# CTRL_MMR0_CFG0 register map
Vendor: Texas Instruments
Registers are 32-bit, read-write, reset 0x0 unless marked. A register's access mark holds for its fields unless they carry their own. Offsets are as the file gives them; [hi:lo] are bit positions; {n}, {i} and the like mark numbered series.

## CTRL_MMR0_CFG0 (part 5 of 10)
0x6504 CFG0_GPU0_GP_IN_ACK_PROXY ro — Acknowledge for GPIO input event from GPU0
  [15] GPU0_GP_IN_ACK_ACK_PROXY — Input acknowledge. The GPU will set this bit to acknowledge a GPIO input request. This will generate a gpu_gpio_ack interrupt which will be cleared when the requestor clears the req bit in the GPU_GP_IN_REQ register.
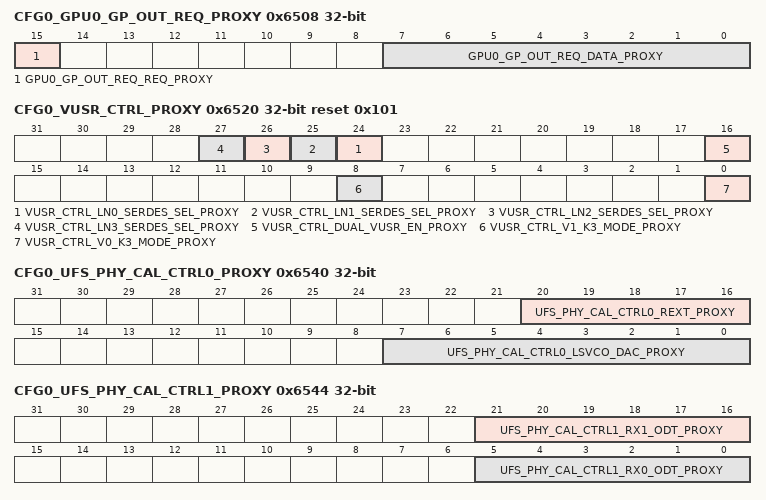
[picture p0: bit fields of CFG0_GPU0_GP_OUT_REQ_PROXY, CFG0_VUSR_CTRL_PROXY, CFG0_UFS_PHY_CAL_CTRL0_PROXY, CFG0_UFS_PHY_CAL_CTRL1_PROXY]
0x6508 CFG0_GPU0_GP_OUT_REQ_PROXY ro — Generates GPIO output event from GPU0
  [15] GPU0_GP_OUT_REQ_REQ_PROXY — Output request. This bit is set to generate a GPIO request from the GPU to read the requestor data output. This will generate a gpu_gpio_req interrupt which will be cleared when the receiver clears the ack bit in the GPU_GPIO_OUT_ACK register. This bit will be cleared by the GPU after the request has been acknowledged.
  [7:0] GPU0_GP_OUT_REQ_DATA_PROXY — GPIO requestor data output from the GPU
0x650C CFG0_GPU0_GP_OUT_ACK_PROXY — Acknowledge for GPIO output event to GPU0
  [15] GPU0_GP_OUT_ACK_ACK_PROXY — Output acknowledge. The receiver of the gpu_gpio_req interrupt will set this bit to acknowledge the GPIO output request. This bit is cleared when the GPU deasserts its gpio_output_req signal.
0x6520 CFG0_VUSR_CTRL_PROXY reset 0x101 — Controls operation of the dual VUSR (Hyperlink) module
  [n+24] VUSR_CTRL_LN{n}_SERDES_SEL_PROXY (n=0..3) — Serdes Selection - Lane {n}The Hyperlink lane{n} interface can be mapped to 2 different SERDES lanes. This bit selects which SERDES drives the VUSR lane{n} PIPE interface input clock, data and control signals. Programming should align with the SERDES0_LN{n}_CTRL and SERDES4_LN{n}_CTRL lane_func_sel programming. 0 - SERDES0 Ln{n} drives VUSR lane{n} inputs 1 - SERDES4 Ln{n} drives VUSR lane{n} inputs
  [16] VUSR_CTRL_DUAL_VUSR_EN_PROXY — Selects single or dual VUSR interface operation 0 - Single VUSR interface (VUSR0) enabled 1 - Dual VUSR interface (VUSR0 & VUSR1) enabled
  [8] VUSR_CTRL_V1_K3_MODE_PROXY — VUSR1 interface operational mode 0 - Legacy (KS2) addressing/interface mode 1 - Enhanced (KS3) addressing/interface mode
  [0] VUSR_CTRL_V0_K3_MODE_PROXY — VUSR0 interface operational mode 0 - Legacy (KS2) addressing/interface mode 1 - Enhanced (KS3) addressing/interface mode
0x6540 CFG0_UFS_PHY_CAL_CTRL0_PROXY — Controls UFS LSVCO calibration
  [20:16] UFS_PHY_CAL_CTRL0_REXT_PROXY — REXT calibration trim value
  [7:0] UFS_PHY_CAL_CTRL0_LSVCO_DAC_PROXY — LS VCO calibration trim value
0x6544 CFG0_UFS_PHY_CAL_CTRL1_PROXY — Controls UFS RX calibration
  [21:16] UFS_PHY_CAL_CTRL1_RX1_ODT_PROXY — RX1 DP/DN 100-ohm differential impedance trim value
  [5:0] UFS_PHY_CAL_CTRL1_RX0_ODT_PROXY — RX0 DP/DN 100-ohm differential impedance trim value
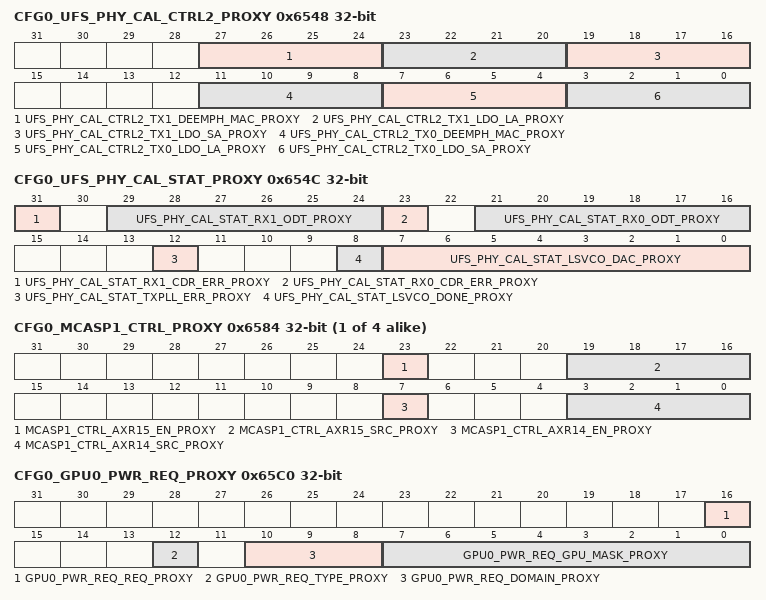
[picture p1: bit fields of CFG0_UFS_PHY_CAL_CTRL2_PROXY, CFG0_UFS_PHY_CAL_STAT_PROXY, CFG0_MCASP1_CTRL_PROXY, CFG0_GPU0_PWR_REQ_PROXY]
0x6548 CFG0_UFS_PHY_CAL_CTRL2_PROXY — Controls UFS TX calibration
  [27:24] UFS_PHY_CAL_CTRL2_TX1_DEEMPH_MAC_PROXY — TX1 DP/DN de-emphasis trim value
  [23:20] UFS_PHY_CAL_CTRL2_TX1_LDO_LA_PROXY — TX1 DP/DN large amplitude trim value
  [19:16] UFS_PHY_CAL_CTRL2_TX1_LDO_SA_PROXY — TX1 DP/DN small amplitude trim value
  [11:8] UFS_PHY_CAL_CTRL2_TX0_DEEMPH_MAC_PROXY — TX0 DP/DN de-emphasis trim value
  [7:4] UFS_PHY_CAL_CTRL2_TX0_LDO_LA_PROXY — TX0 DP/DN large amplitude trim value
  [3:0] UFS_PHY_CAL_CTRL2_TX0_LDO_SA_PROXY — TX0 DP/DN small amplitude trim value
0x654C CFG0_UFS_PHY_CAL_STAT_PROXY ro — Shows UFS calibration procedure results
  [31] UFS_PHY_CAL_STAT_RX1_CDR_ERR_PROXY — RX1 CDR calibration timeout error
  [29:24] UFS_PHY_CAL_STAT_RX1_ODT_PROXY — RX1 DP/DN ODT calibration result
  [23] UFS_PHY_CAL_STAT_RX0_CDR_ERR_PROXY — RX0 CDR calibration timeout error
  [21:16] UFS_PHY_CAL_STAT_RX0_ODT_PROXY — RX0 DP/DN ODT calibration result
  [12] UFS_PHY_CAL_STAT_TXPLL_ERR_PROXY — TX calibration timeout error
  [8] UFS_PHY_CAL_STAT_LSVCO_DONE_PROXY — LS VCO calibration trim done
  [7:0] UFS_PHY_CAL_STAT_LSVCO_DAC_PROXY — LS VCO calibration trim result
{0x6580+4i} CFG0_MCASP{i}_CTRL_PROXY (i=1..4) — Controls McASP{i} operation
  [23] MCASP{i}_CTRL_AXR15_EN_PROXY — Enable AXR15 receive data. 0 - AXR15 input driven 1'b0 1 - AXR15 input driven by AFSR/X input selected by axr15_src value
  [19:16] MCASP{i}_CTRL_AXR15_SRC_PROXY — Selects one of the AFSX or AFSR inputs as the AXR15 data input Field values (Others are reserved): 4'b0000 - McASP0_AFSR 4'b0001 - McASP0_AFSX 4'b0010 - McASP1_AFSR 4'b0011 - McASP1_AFSX 4'b0100 - McASP2_AFSR 4'b0101 - McASP2_AFSX 4'b0110 - McASP3_AFSR 4'b0111 - McASP3_AFSX 4'b1000 - McASP4_AFSR 4'b1001 - McASP4_AFSX 4'b1010 - 0 4'b1011 - 0 4'b1100 - 0 4'b1101 - 0 4'b1110 - 0 4'b1111 - 0
  [7] MCASP{i}_CTRL_AXR14_EN_PROXY — Enable AXR14 receive data. 0 - AXR14 input driven 1'b0 1 - AXR14 input driven by AFSR/X input selected by axr14_src value
  [3:0] MCASP{i}_CTRL_AXR14_SRC_PROXY — Selects one of the AFSX or AFSR inputs as the AXR14 data input Field values (Others are reserved): 4'b0000 - McASP0_AFSR 4'b0001 - McASP0_AFSX 4'b0010 - McASP1_AFSR 4'b0011 - McASP1_AFSX 4'b0100 - McASP2_AFSR 4'b0101 - McASP2_AFSX 4'b0110 - McASP3_AFSR 4'b0111 - McASP3_AFSX 4'b1000 - McASP4_AFSR 4'b1001 - McASP4_AFSX 4'b1010 - 0 4'b1011 - 0 4'b1100 - 0 4'b1101 - 0 4'b1110 - 0 4'b1111 - 0
0x65C0 CFG0_GPU0_PWR_REQ_PROXY ro — Indicates GPU0 power control interface requests
  [16] GPU0_PWR_REQ_REQ_PROXY — Power control request. This bit is set by the GPU to request a Power Management event to the PM processor. This will generate a gpu0_pwr_req interrupt. The interrupt is cleared only when the GPU clears its pwrctrl_gpu_req output.
  [12] GPU0_PWR_REQ_TYPE_PROXY — GPU request type. 0 - Power Down request 1 - Power Up request
  [10:8] GPU0_PWR_REQ_DOMAIN_PROXY — GPU request mask. Indicates GPU domain to which the power event applies. For mapping refer to GPU RGX_CR_POWER_EVENT register.
  [7:0] GPU0_PWR_REQ_GPU_MASK_PROXY — GPU request mask. One bit per GPU indicating to which GPUs the power event applies. Mask bits are indexed by GPU_ID
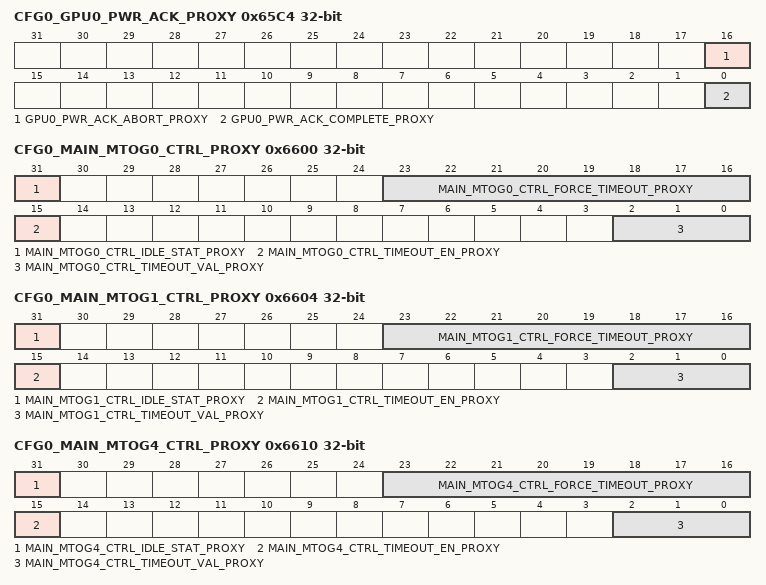
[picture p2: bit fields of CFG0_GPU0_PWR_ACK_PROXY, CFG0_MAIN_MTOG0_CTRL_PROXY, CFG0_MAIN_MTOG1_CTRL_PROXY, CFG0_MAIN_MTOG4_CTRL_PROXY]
0x65C4 CFG0_GPU0_PWR_ACK_PROXY — Controls GPU0 power control interface request acknowledgement
  [16] GPU0_PWR_ACK_ABORT_PROXY — Power control abort. This bit is set by the PM processor to that the GPU power control request could not be completed. The bit is cleared to 0 when gpu0_pwr_req goes low.
  [0] GPU0_PWR_ACK_COMPLETE_PROXY — Power control complete. This bit is set by the PM processor to indicate sucessful completion of the GPU power control request. The bit is cleared to 0 when gpu0_pwr_req goes low.
0x6600 CFG0_MAIN_MTOG0_CTRL_PROXY access per field — Controls timeout operation of read transactions from the GIC master port
  [31] MAIN_MTOG0_CTRL_IDLE_STAT_PROXY ro — Idle statusWhen high, indicates MTOG0 is idle.
  [23:16] MAIN_MTOG0_CTRL_FORCE_TIMEOUT_PROXY rw — Force TimeoutForces a flush of the interface transactions. This bitfield is only relevant if timeout_en=1. After forcing a timeout by writing the encoded value, the force_timeout and timeout_en bitfields must be cleared to clear the timeout before re-enabling the gasket. 8'h95 - Force a gasket timeoutAll others - Normal operation
  [15] MAIN_MTOG0_CTRL_TIMEOUT_EN_PROXY rw — Timeout Enable 1'b0 - Disable the gasket. Clear the interrupt and reset the counter 1'b1 - Enable the timeout gasket functions
  [2:0] MAIN_MTOG0_CTRL_TIMEOUT_VAL_PROXY rw — Gasket Timeout ValueSelects the number of clock cycles before the interface is considered to have timed out Field values (Others are reserved): 3'b000 - 1024 clock cycles 3'b001 - 4096 clock cycles 3'b010 - 16,384 clock cycles 3'b011 - 65,536 clock cycles 3'b100 - 262,144 clock cycles 3'b101 - 1,048,576 clock cycles 3'b110 - 2,097,152 clock cycles 3'b111 - 4,194,303 clock cycles
0x6604 CFG0_MAIN_MTOG1_CTRL_PROXY access per field — Controls timeout operation of write transactions from the GIC master port
  [31] MAIN_MTOG1_CTRL_IDLE_STAT_PROXY ro — Idle statusWhen high, indicates MTOG1 is idle.
  [23:16] MAIN_MTOG1_CTRL_FORCE_TIMEOUT_PROXY rw — Force TimeoutForces a flush of the interface transactions. This bitfield is only relevant if timeout_en=1. After forcing a timeout by writing the encoded value, the force_timeout and timeout_en bitfields must be cleared to clear the timeout before re-enabling the gasket. 8'h95 - Force a gasket timeoutAll others - Normal operation
  [15] MAIN_MTOG1_CTRL_TIMEOUT_EN_PROXY rw — Timeout Enable 1'b0 - Disable the gasket. Clear the interrupt and reset the counter 1'b1 - Enable the timeout gasket functions
  [2:0] MAIN_MTOG1_CTRL_TIMEOUT_VAL_PROXY rw — Gasket Timeout ValueSelects the number of clock cycles before the interface is considered to have timed out Field values (Others are reserved): 3'b000 - 1024 clock cycles 3'b001 - 4096 clock cycles 3'b010 - 16,384 clock cycles 3'b011 - 65,536 clock cycles 3'b100 - 262,144 clock cycles 3'b101 - 1,048,576 clock cycles 3'b110 - 2,097,152 clock cycles 3'b111 - 4,194,303 clock cycles
0x6610 CFG0_MAIN_MTOG4_CTRL_PROXY access per field — Controls timeout operation of read transactions from the eMMC1 master port
  [31] MAIN_MTOG4_CTRL_IDLE_STAT_PROXY ro — Idle statusWhen high, indicates MTOG4 is idle.
  [23:16] MAIN_MTOG4_CTRL_FORCE_TIMEOUT_PROXY rw — Force TimeoutForces a flush of the interface transactions. This bitfield is only relevant if timeout_en=1. After forcing a timeout by writing the encoded value, the force_timeout and timeout_en bitfields must be cleared to clear the timeout before re-enabling the gasket. 8'h95 - Force a gasket timeoutAll others - Normal operation
  [15] MAIN_MTOG4_CTRL_TIMEOUT_EN_PROXY rw — Timeout Enable 1'b0 - Disable the gasket. Clear the interrupt and reset the counter 1'b1 - Enable the timeout gasket functions
  [2:0] MAIN_MTOG4_CTRL_TIMEOUT_VAL_PROXY rw — Gasket Timeout ValueSelects the number of clock cycles before the interface is considered to have timed out Field values (Others are reserved): 3'b000 - 1024 clock cycles 3'b001 - 4096 clock cycles 3'b010 - 16,384 clock cycles 3'b011 - 65,536 clock cycles 3'b100 - 262,144 clock cycles 3'b101 - 1,048,576 clock cycles 3'b110 - 2,097,152 clock cycles 3'b111 - 4,194,303 clock cycles
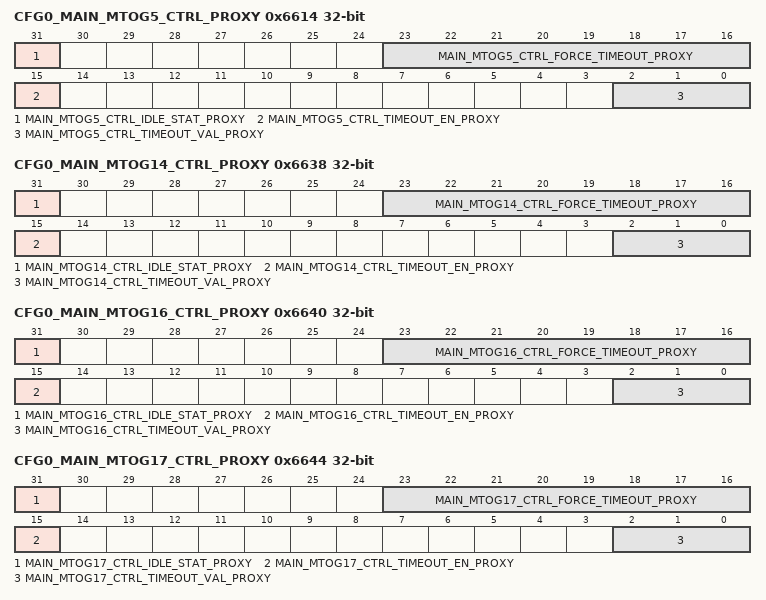
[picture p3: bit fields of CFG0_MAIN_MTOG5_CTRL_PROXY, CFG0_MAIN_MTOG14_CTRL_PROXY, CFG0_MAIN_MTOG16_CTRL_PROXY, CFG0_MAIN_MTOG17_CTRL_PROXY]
0x6614 CFG0_MAIN_MTOG5_CTRL_PROXY access per field — Controls timeout operation of write transactions from the eMMC1 master port
  [31] MAIN_MTOG5_CTRL_IDLE_STAT_PROXY ro — Idle statusWhen high, indicates MTOG5 is idle.
  [23:16] MAIN_MTOG5_CTRL_FORCE_TIMEOUT_PROXY rw — Force TimeoutForces a flush of the interface transactions. This bitfield is only relevant if timeout_en=1. After forcing a timeout by writing the encoded value, the force_timeout and timeout_en bitfields must be cleared to clear the timeout before re-enabling the gasket. 8'h95 - Force a gasket timeoutAll others - Normal operation
  [15] MAIN_MTOG5_CTRL_TIMEOUT_EN_PROXY rw — Timeout Enable 1'b0 - Disable the gasket. Clear the interrupt and reset the counter 1'b1 - Enable the timeout gasket functions
  [2:0] MAIN_MTOG5_CTRL_TIMEOUT_VAL_PROXY rw — Gasket Timeout ValueSelects the number of clock cycles before the interface is considered to have timed out Field values (Others are reserved): 3'b000 - 1024 clock cycles 3'b001 - 4096 clock cycles 3'b010 - 16,384 clock cycles 3'b011 - 65,536 clock cycles 3'b100 - 262,144 clock cycles 3'b101 - 1,048,576 clock cycles 3'b110 - 2,097,152 clock cycles 3'b111 - 4,194,303 clock cycles
0x6638 CFG0_MAIN_MTOG14_CTRL_PROXY access per field — Controls timeout operation of transactions from the NavSS PVU to VIRTSS
  [31] MAIN_MTOG14_CTRL_IDLE_STAT_PROXY ro — Idle statusWhen high, indicates MTOG14 is idle.
  [23:16] MAIN_MTOG14_CTRL_FORCE_TIMEOUT_PROXY rw — Force TimeoutForces a flush of the interface transactions. This bitfield is only relevant if timeout_en=1. After forcing a timeout by writing the encoded value, the force_timeout and timeout_en bitfields must be cleared to clear the timeout before re-enabling the gasket. 8'h95 - Force a gasket timeoutAll others - Normal operation
  [15] MAIN_MTOG14_CTRL_TIMEOUT_EN_PROXY rw — Timeout Enable 1'b0 - Disable the gasket. Clear the interrupt and reset the counter 1'b1 - Enable the timeout gasket functions
  [2:0] MAIN_MTOG14_CTRL_TIMEOUT_VAL_PROXY rw — Gasket Timeout ValueSelects the number of clock cycles before the interface is considered to have timed out Field values (Others are reserved): 3'b000 - 1024 clock cycles 3'b001 - 4096 clock cycles 3'b010 - 16,384 clock cycles 3'b011 - 65,536 clock cycles 3'b100 - 262,144 clock cycles 3'b101 - 1,048,576 clock cycles 3'b110 - 2,097,152 clock cycles 3'b111 - 4,194,303 clock cycles
0x6640 CFG0_MAIN_MTOG16_CTRL_PROXY access per field — Controls timeout operation of read transactions from the MAIN R5 Clstr0 Core0 VBUSM Memory master port
  [31] MAIN_MTOG16_CTRL_IDLE_STAT_PROXY ro — Idle statusWhen high, indicates MTOG16 is idle.
  [23:16] MAIN_MTOG16_CTRL_FORCE_TIMEOUT_PROXY rw — Force TimeoutForces a flush of the interface transactions. This bitfield is only relevant if timeout_en=1. After forcing a timeout by writing the encoded value, the force_timeout and timeout_en bitfields must be cleared to clear the timeout before re-enabling the gasket. 8'h95 - Force a gasket timeoutAll others - Normal operation
  [15] MAIN_MTOG16_CTRL_TIMEOUT_EN_PROXY rw — Timeout Enable 1'b0 - Disable the gasket. Clear the interrupt and reset the counter 1'b1 - Enable the timeout gasket functions
  [2:0] MAIN_MTOG16_CTRL_TIMEOUT_VAL_PROXY rw — Gasket Timeout ValueSelects the number of clock cycles before the interface is considered to have timed out Field values (Others are reserved): 3'b000 - 1024 clock cycles 3'b001 - 4096 clock cycles 3'b010 - 16,384 clock cycles 3'b011 - 65,536 clock cycles 3'b100 - 262,144 clock cycles 3'b101 - 1,048,576 clock cycles 3'b110 - 2,097,152 clock cycles 3'b111 - 4,194,303 clock cycles
0x6644 CFG0_MAIN_MTOG17_CTRL_PROXY access per field — Controls timeout operation of write transactions from the MAIN R5 Clstr0 Core0 VBUSM Memory master port
  [31] MAIN_MTOG17_CTRL_IDLE_STAT_PROXY ro — Idle statusWhen high, indicates MTOG17 is idle.
  [23:16] MAIN_MTOG17_CTRL_FORCE_TIMEOUT_PROXY rw — Force TimeoutForces a flush of the interface transactions. This bitfield is only relevant if timeout_en=1. After forcing a timeout by writing the encoded value, the force_timeout and timeout_en bitfields must be cleared to clear the timeout before re-enabling the gasket. 8'h95 - Force a gasket timeoutAll others - Normal operation
  [15] MAIN_MTOG17_CTRL_TIMEOUT_EN_PROXY rw — Timeout Enable 1'b0 - Disable the gasket. Clear the interrupt and reset the counter 1'b1 - Enable the timeout gasket functions
  [2:0] MAIN_MTOG17_CTRL_TIMEOUT_VAL_PROXY rw — Gasket Timeout ValueSelects the number of clock cycles before the interface is considered to have timed out Field values (Others are reserved): 3'b000 - 1024 clock cycles 3'b001 - 4096 clock cycles 3'b010 - 16,384 clock cycles 3'b011 - 65,536 clock cycles 3'b100 - 262,144 clock cycles 3'b101 - 1,048,576 clock cycles 3'b110 - 2,097,152 clock cycles 3'b111 - 4,194,303 clock cycles
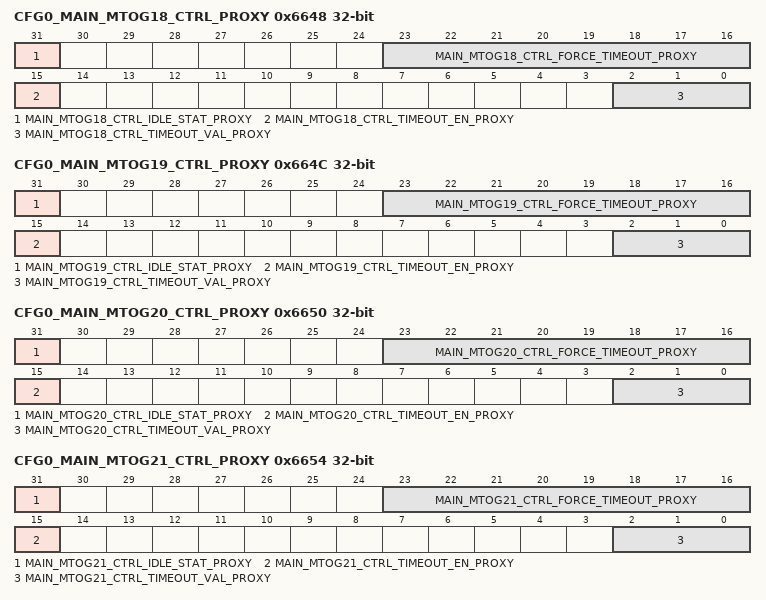
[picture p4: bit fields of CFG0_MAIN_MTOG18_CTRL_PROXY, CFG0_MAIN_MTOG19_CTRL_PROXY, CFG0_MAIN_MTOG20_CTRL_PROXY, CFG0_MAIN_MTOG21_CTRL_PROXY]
0x6648 CFG0_MAIN_MTOG18_CTRL_PROXY access per field — Controls timeout operation of read transactions from the MAIN R5 Clstr0 Core1 VBUSM Memory master port
  [31] MAIN_MTOG18_CTRL_IDLE_STAT_PROXY ro — Idle statusWhen high, indicates MTOG18 is idle.
  [23:16] MAIN_MTOG18_CTRL_FORCE_TIMEOUT_PROXY rw — Force TimeoutForces a flush of the interface transactions. This bitfield is only relevant if timeout_en=1. After forcing a timeout by writing the encoded value, the force_timeout and timeout_en bitfields must be cleared to clear the timeout before re-enabling the gasket. 8'h95 - Force a gasket timeoutAll others - Normal operation
  [15] MAIN_MTOG18_CTRL_TIMEOUT_EN_PROXY rw — Timeout Enable 1'b0 - Disable the gasket. Clear the interrupt and reset the counter 1'b1 - Enable the timeout gasket functions
  [2:0] MAIN_MTOG18_CTRL_TIMEOUT_VAL_PROXY rw — Gasket Timeout ValueSelects the number of clock cycles before the interface is considered to have timed out Field values (Others are reserved): 3'b000 - 1024 clock cycles 3'b001 - 4096 clock cycles 3'b010 - 16,384 clock cycles 3'b011 - 65,536 clock cycles 3'b100 - 262,144 clock cycles 3'b101 - 1,048,576 clock cycles 3'b110 - 2,097,152 clock cycles 3'b111 - 4,194,303 clock cycles
0x664C CFG0_MAIN_MTOG19_CTRL_PROXY access per field — Controls timeout operation of write transactions from the MAIN R5 Clstr0 Core1 VBUSM Memory master port
  [31] MAIN_MTOG19_CTRL_IDLE_STAT_PROXY ro — Idle statusWhen high, indicates MTOG19 is idle.
  [23:16] MAIN_MTOG19_CTRL_FORCE_TIMEOUT_PROXY rw — Force TimeoutForces a flush of the interface transactions. This bitfield is only relevant if timeout_en=1. After forcing a timeout by writing the encoded value, the force_timeout and timeout_en bitfields must be cleared to clear the timeout before re-enabling the gasket. 8'h95 - Force a gasket timeoutAll others - Normal operation
  [15] MAIN_MTOG19_CTRL_TIMEOUT_EN_PROXY rw — Timeout Enable 1'b0 - Disable the gasket. Clear the interrupt and reset the counter 1'b1 - Enable the timeout gasket functions
  [2:0] MAIN_MTOG19_CTRL_TIMEOUT_VAL_PROXY rw — Gasket Timeout ValueSelects the number of clock cycles before the interface is considered to have timed out Field values (Others are reserved): 3'b000 - 1024 clock cycles 3'b001 - 4096 clock cycles 3'b010 - 16,384 clock cycles 3'b011 - 65,536 clock cycles 3'b100 - 262,144 clock cycles 3'b101 - 1,048,576 clock cycles 3'b110 - 2,097,152 clock cycles 3'b111 - 4,194,303 clock cycles
0x6650 CFG0_MAIN_MTOG20_CTRL_PROXY access per field — Controls timeout operation of read transactions from the MAIN R5 Clstr1 Core0 VBUSM Memory master port
  [31] MAIN_MTOG20_CTRL_IDLE_STAT_PROXY ro — Idle statusWhen high, indicates MTOG20 is idle.
  [23:16] MAIN_MTOG20_CTRL_FORCE_TIMEOUT_PROXY rw — Force TimeoutForces a flush of the interface transactions. This bitfield is only relevant if timeout_en=1. After forcing a timeout by writing the encoded value, the force_timeout and timeout_en bitfields must be cleared to clear the timeout before re-enabling the gasket. 8'h95 - Force a gasket timeoutAll others - Normal operation
  [15] MAIN_MTOG20_CTRL_TIMEOUT_EN_PROXY rw — Timeout Enable 1'b0 - Disable the gasket. Clear the interrupt and reset the counter 1'b1 - Enable the timeout gasket functions
  [2:0] MAIN_MTOG20_CTRL_TIMEOUT_VAL_PROXY rw — Gasket Timeout ValueSelects the number of clock cycles before the interface is considered to have timed out Field values (Others are reserved): 3'b000 - 1024 clock cycles 3'b001 - 4096 clock cycles 3'b010 - 16,384 clock cycles 3'b011 - 65,536 clock cycles 3'b100 - 262,144 clock cycles 3'b101 - 1,048,576 clock cycles 3'b110 - 2,097,152 clock cycles 3'b111 - 4,194,303 clock cycles
0x6654 CFG0_MAIN_MTOG21_CTRL_PROXY access per field — Controls timeout operation of write transactions from the MAIN R5 Clstr1 Core0 VBUSM Memory master port
  [31] MAIN_MTOG21_CTRL_IDLE_STAT_PROXY ro — Idle statusWhen high, indicates MTOG21 is idle.
  [23:16] MAIN_MTOG21_CTRL_FORCE_TIMEOUT_PROXY rw — Force TimeoutForces a flush of the interface transactions. This bitfield is only relevant if timeout_en=1. After forcing a timeout by writing the encoded value, the force_timeout and timeout_en bitfields must be cleared to clear the timeout before re-enabling the gasket. 8'h95 - Force a gasket timeoutAll others - Normal operation
  [15] MAIN_MTOG21_CTRL_TIMEOUT_EN_PROXY rw — Timeout Enable 1'b0 - Disable the gasket. Clear the interrupt and reset the counter 1'b1 - Enable the timeout gasket functions
  [2:0] MAIN_MTOG21_CTRL_TIMEOUT_VAL_PROXY rw — Gasket Timeout ValueSelects the number of clock cycles before the interface is considered to have timed out Field values (Others are reserved): 3'b000 - 1024 clock cycles 3'b001 - 4096 clock cycles 3'b010 - 16,384 clock cycles 3'b011 - 65,536 clock cycles 3'b100 - 262,144 clock cycles 3'b101 - 1,048,576 clock cycles 3'b110 - 2,097,152 clock cycles 3'b111 - 4,194,303 clock cycles
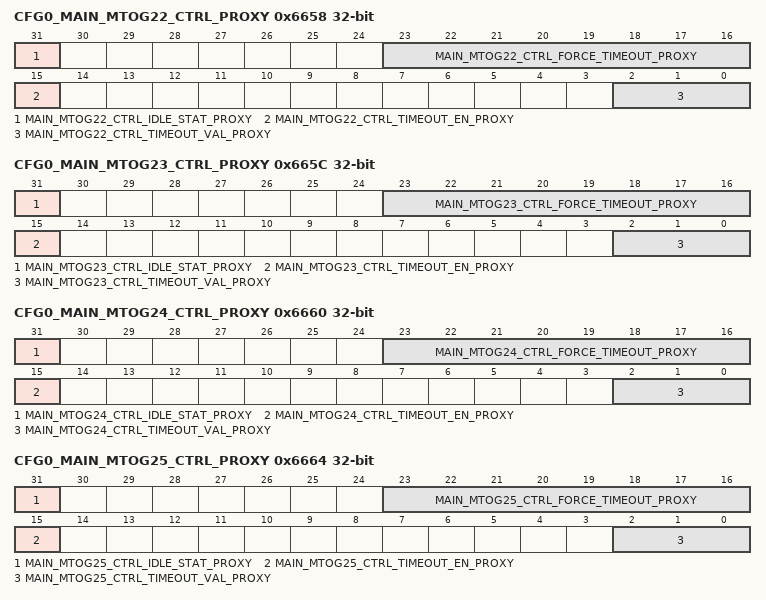
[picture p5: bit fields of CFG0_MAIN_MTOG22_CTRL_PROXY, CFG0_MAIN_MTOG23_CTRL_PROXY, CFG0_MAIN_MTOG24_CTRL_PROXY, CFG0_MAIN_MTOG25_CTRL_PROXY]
0x6658 CFG0_MAIN_MTOG22_CTRL_PROXY access per field — Controls timeout operation of read transactions from the MAIN R5 Clstr1 Core1 VBUSM Memory master port
  [31] MAIN_MTOG22_CTRL_IDLE_STAT_PROXY ro — Idle statusWhen high, indicates MTOG22 is idle.
  [23:16] MAIN_MTOG22_CTRL_FORCE_TIMEOUT_PROXY rw — Force TimeoutForces a flush of the interface transactions. This bitfield is only relevant if timeout_en=1. After forcing a timeout by writing the encoded value, the force_timeout and timeout_en bitfields must be cleared to clear the timeout before re-enabling the gasket. 8'h95 - Force a gasket timeoutAll others - Normal operation
  [15] MAIN_MTOG22_CTRL_TIMEOUT_EN_PROXY rw — Timeout Enable 1'b0 - Disable the gasket. Clear the interrupt and reset the counter 1'b1 - Enable the timeout gasket functions
  [2:0] MAIN_MTOG22_CTRL_TIMEOUT_VAL_PROXY rw — Gasket Timeout ValueSelects the number of clock cycles before the interface is considered to have timed out Field values (Others are reserved): 3'b000 - 1024 clock cycles 3'b001 - 4096 clock cycles 3'b010 - 16,384 clock cycles 3'b011 - 65,536 clock cycles 3'b100 - 262,144 clock cycles 3'b101 - 1,048,576 clock cycles 3'b110 - 2,097,152 clock cycles 3'b111 - 4,194,303 clock cycles
0x665C CFG0_MAIN_MTOG23_CTRL_PROXY access per field — Controls timeout operation of write transactions from the MAIN R5 Clstr1 Core 1 VBUSM Memory master port
  [31] MAIN_MTOG23_CTRL_IDLE_STAT_PROXY ro — Idle statusWhen high, indicates MTOG23 is idle.
  [23:16] MAIN_MTOG23_CTRL_FORCE_TIMEOUT_PROXY rw — Force TimeoutForces a flush of the interface transactions. This bitfield is only relevant if timeout_en=1. After forcing a timeout by writing the encoded value, the force_timeout and timeout_en bitfields must be cleared to clear the timeout before re-enabling the gasket. 8'h95 - Force a gasket timeoutAll others - Normal operation
  [15] MAIN_MTOG23_CTRL_TIMEOUT_EN_PROXY rw — Timeout Enable 1'b0 - Disable the gasket. Clear the interrupt and reset the counter 1'b1 - Enable the timeout gasket functions
  [2:0] MAIN_MTOG23_CTRL_TIMEOUT_VAL_PROXY rw — Gasket Timeout ValueSelects the number of clock cycles before the interface is considered to have timed out Field values (Others are reserved): 3'b000 - 1024 clock cycles 3'b001 - 4096 clock cycles 3'b010 - 16,384 clock cycles 3'b011 - 65,536 clock cycles 3'b100 - 262,144 clock cycles 3'b101 - 1,048,576 clock cycles 3'b110 - 2,097,152 clock cycles 3'b111 - 4,194,303 clock cycles
0x6660 CFG0_MAIN_MTOG24_CTRL_PROXY access per field — Controls timeout operation of real time transactions from High Speed IO masters
  [31] MAIN_MTOG24_CTRL_IDLE_STAT_PROXY ro — Idle statusWhen high, indicates MTOG24 is idle.
  [23:16] MAIN_MTOG24_CTRL_FORCE_TIMEOUT_PROXY rw — Force TimeoutForces a flush of the interface transactions. This bitfield is only relevant if timeout_en=1. After forcing a timeout by writing the encoded value, the force_timeout and timeout_en bitfields must be cleared to clear the timeout before re-enabling the gasket. 8'h95 - Force a gasket timeoutAll others - Normal operation
  [15] MAIN_MTOG24_CTRL_TIMEOUT_EN_PROXY rw — Timeout Enable 1'b0 - Disable the gasket. Clear the interrupt and reset the counter 1'b1 - Enable the timeout gasket functions
  [2:0] MAIN_MTOG24_CTRL_TIMEOUT_VAL_PROXY rw — Gasket Timeout ValueSelects the number of clock cycles before the interface is considered to have timed out Field values (Others are reserved): 3'b000 - 1024 clock cycles 3'b001 - 4096 clock cycles 3'b010 - 16,384 clock cycles 3'b011 - 65,536 clock cycles 3'b100 - 262,144 clock cycles 3'b101 - 1,048,576 clock cycles 3'b110 - 2,097,152 clock cycles 3'b111 - 4,194,303 clock cycles
0x6664 CFG0_MAIN_MTOG25_CTRL_PROXY access per field — Controls timeout operation of non-real time transactions from High Speed IO masters
  [31] MAIN_MTOG25_CTRL_IDLE_STAT_PROXY ro — Idle statusWhen high, indicates MTOG25 is idle.
  [23:16] MAIN_MTOG25_CTRL_FORCE_TIMEOUT_PROXY rw — Force TimeoutForces a flush of the interface transactions. This bitfield is only relevant if timeout_en=1. After forcing a timeout by writing the encoded value, the force_timeout and timeout_en bitfields must be cleared to clear the timeout before re-enabling the gasket. 8'h95 - Force a gasket timeoutAll others - Normal operation
  [15] MAIN_MTOG25_CTRL_TIMEOUT_EN_PROXY rw — Timeout Enable 1'b0 - Disable the gasket. Clear the interrupt and reset the counter 1'b1 - Enable the timeout gasket functions
  [2:0] MAIN_MTOG25_CTRL_TIMEOUT_VAL_PROXY rw — Gasket Timeout ValueSelects the number of clock cycles before the interface is considered to have timed out Field values (Others are reserved): 3'b000 - 1024 clock cycles 3'b001 - 4096 clock cycles 3'b010 - 16,384 clock cycles 3'b011 - 65,536 clock cycles 3'b100 - 262,144 clock cycles 3'b101 - 1,048,576 clock cycles 3'b110 - 2,097,152 clock cycles 3'b111 - 4,194,303 clock cycles
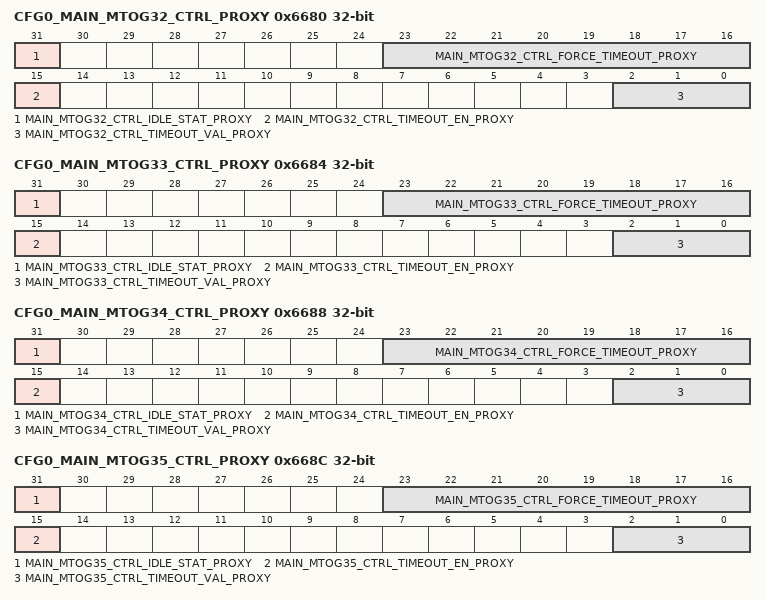
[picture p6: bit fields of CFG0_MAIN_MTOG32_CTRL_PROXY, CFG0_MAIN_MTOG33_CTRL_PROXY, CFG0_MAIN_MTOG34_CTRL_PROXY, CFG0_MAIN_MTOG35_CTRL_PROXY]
0x6680 CFG0_MAIN_MTOG32_CTRL_PROXY access per field — Controls timeout operation of Accelerator Cluster ASIL-B master accesses to MSMC (L2) SRAM
  [31] MAIN_MTOG32_CTRL_IDLE_STAT_PROXY ro — Idle statusWhen high, indicates MTOG32 is idle.
  [23:16] MAIN_MTOG32_CTRL_FORCE_TIMEOUT_PROXY rw — Force TimeoutForces a flush of the interface transactions. This bitfield is only relevant if timeout_en=1. After forcing a timeout by writing the encoded value, the force_timeout and timeout_en bitfields must be cleared to clear the timeout before re-enabling the gasket. 8'h95 - Force a gasket timeoutAll others - Normal operation
  [15] MAIN_MTOG32_CTRL_TIMEOUT_EN_PROXY rw — Timeout Enable 1'b0 - Disable the gasket. Clear the interrupt and reset the counter 1'b1 - Enable the timeout gasket functions
  [2:0] MAIN_MTOG32_CTRL_TIMEOUT_VAL_PROXY rw — Gasket Timeout ValueSelects the number of clock cycles before the interface is considered to have timed out Field values (Others are reserved): 3'b000 - 1024 clock cycles 3'b001 - 4096 clock cycles 3'b010 - 16,384 clock cycles 3'b011 - 65,536 clock cycles 3'b100 - 262,144 clock cycles 3'b101 - 1,048,576 clock cycles 3'b110 - 2,097,152 clock cycles 3'b111 - 4,194,303 clock cycles
0x6684 CFG0_MAIN_MTOG33_CTRL_PROXY access per field — Controls timeout operation of Accelerator Cluster QueueManager master accesses to MSMC (L2) SRAM
  [31] MAIN_MTOG33_CTRL_IDLE_STAT_PROXY ro — Idle statusWhen high, indicates MTOG33 is idle.
  [23:16] MAIN_MTOG33_CTRL_FORCE_TIMEOUT_PROXY rw — Force TimeoutForces a flush of the interface transactions. This bitfield is only relevant if timeout_en=1. After forcing a timeout by writing the encoded value, the force_timeout and timeout_en bitfields must be cleared to clear the timeout before re-enabling the gasket. 8'h95 - Force a gasket timeoutAll others - Normal operation
  [15] MAIN_MTOG33_CTRL_TIMEOUT_EN_PROXY rw — Timeout Enable 1'b0 - Disable the gasket. Clear the interrupt and reset the counter 1'b1 - Enable the timeout gasket functions
  [2:0] MAIN_MTOG33_CTRL_TIMEOUT_VAL_PROXY rw — Gasket Timeout ValueSelects the number of clock cycles before the interface is considered to have timed out Field values (Others are reserved): 3'b000 - 1024 clock cycles 3'b001 - 4096 clock cycles 3'b010 - 16,384 clock cycles 3'b011 - 65,536 clock cycles 3'b100 - 262,144 clock cycles 3'b101 - 1,048,576 clock cycles 3'b110 - 2,097,152 clock cycles 3'b111 - 4,194,303 clock cycles
0x6688 CFG0_MAIN_MTOG34_CTRL_PROXY access per field — Controls timeout operation of Accelerator Cluster ASIL-B master accesses to DDR for OrderIDs 0-4
  [31] MAIN_MTOG34_CTRL_IDLE_STAT_PROXY ro — Idle statusWhen high, indicates MTOG34 is idle.
  [23:16] MAIN_MTOG34_CTRL_FORCE_TIMEOUT_PROXY rw — Force TimeoutForces a flush of the interface transactions. This bitfield is only relevant if timeout_en=1. After forcing a timeout by writing the encoded value, the force_timeout and timeout_en bitfields must be cleared to clear the timeout before re-enabling the gasket. 8'h95 - Force a gasket timeoutAll others - Normal operation
  [15] MAIN_MTOG34_CTRL_TIMEOUT_EN_PROXY rw — Timeout Enable 1'b0 - Disable the gasket. Clear the interrupt and reset the counter 1'b1 - Enable the timeout gasket functions
  [2:0] MAIN_MTOG34_CTRL_TIMEOUT_VAL_PROXY rw — Gasket Timeout ValueSelects the number of clock cycles before the interface is considered to have timed out Field values (Others are reserved): 3'b000 - 1024 clock cycles 3'b001 - 4096 clock cycles 3'b010 - 16,384 clock cycles 3'b011 - 65,536 clock cycles 3'b100 - 262,144 clock cycles 3'b101 - 1,048,576 clock cycles 3'b110 - 2,097,152 clock cycles 3'b111 - 4,194,303 clock cycles
0x668C CFG0_MAIN_MTOG35_CTRL_PROXY access per field — Controls timeout operation of Accelerator Cluster QueueManager master accesses to DDR fro OrderIDs 0-4
  [31] MAIN_MTOG35_CTRL_IDLE_STAT_PROXY ro — Idle statusWhen high, indicates MTOG35 is idle.
  [23:16] MAIN_MTOG35_CTRL_FORCE_TIMEOUT_PROXY rw — Force TimeoutForces a flush of the interface transactions. This bitfield is only relevant if timeout_en=1. After forcing a timeout by writing the encoded value, the force_timeout and timeout_en bitfields must be cleared to clear the timeout before re-enabling the gasket. 8'h95 - Force a gasket timeoutAll others - Normal operation
  [15] MAIN_MTOG35_CTRL_TIMEOUT_EN_PROXY rw — Timeout Enable 1'b0 - Disable the gasket. Clear the interrupt and reset the counter 1'b1 - Enable the timeout gasket functions
  [2:0] MAIN_MTOG35_CTRL_TIMEOUT_VAL_PROXY rw — Gasket Timeout ValueSelects the number of clock cycles before the interface is considered to have timed out Field values (Others are reserved): 3'b000 - 1024 clock cycles 3'b001 - 4096 clock cycles 3'b010 - 16,384 clock cycles 3'b011 - 65,536 clock cycles 3'b100 - 262,144 clock cycles 3'b101 - 1,048,576 clock cycles 3'b110 - 2,097,152 clock cycles 3'b111 - 4,194,303 clock cycles
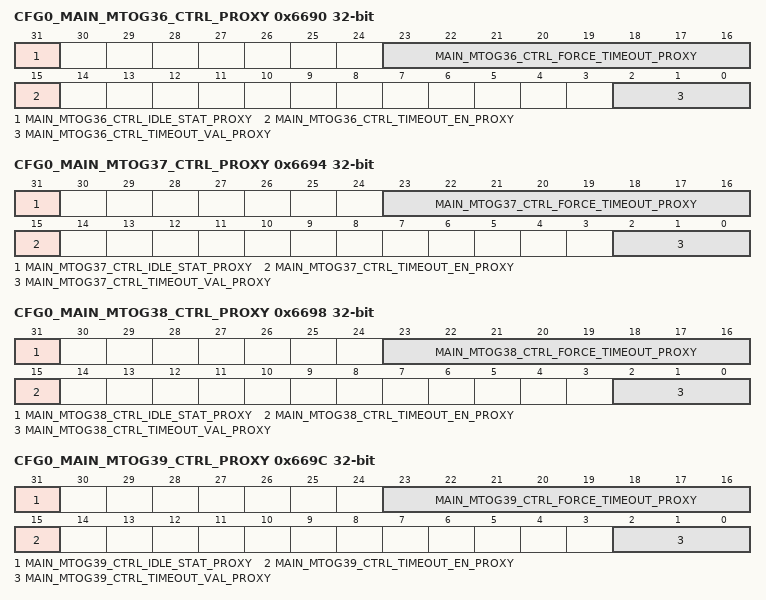
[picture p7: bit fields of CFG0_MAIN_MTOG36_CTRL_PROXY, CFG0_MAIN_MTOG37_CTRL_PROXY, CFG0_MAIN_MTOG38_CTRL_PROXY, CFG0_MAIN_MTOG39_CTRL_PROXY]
0x6690 CFG0_MAIN_MTOG36_CTRL_PROXY access per field — Controls timeout operation of Accelerator Cluster ASIL-B master accesses to DDR for OrderIDs 5-9
  [31] MAIN_MTOG36_CTRL_IDLE_STAT_PROXY ro — Idle statusWhen high, indicates MTOG36 is idle.
  [23:16] MAIN_MTOG36_CTRL_FORCE_TIMEOUT_PROXY rw — Force TimeoutForces a flush of the interface transactions. This bitfield is only relevant if timeout_en=1. After forcing a timeout by writing the encoded value, the force_timeout and timeout_en bitfields must be cleared to clear the timeout before re-enabling the gasket. 8'h95 - Force a gasket timeoutAll others - Normal operation
  [15] MAIN_MTOG36_CTRL_TIMEOUT_EN_PROXY rw — Timeout Enable 1'b0 - Disable the gasket. Clear the interrupt and reset the counter 1'b1 - Enable the timeout gasket functions
  [2:0] MAIN_MTOG36_CTRL_TIMEOUT_VAL_PROXY rw — Gasket Timeout ValueSelects the number of clock cycles before the interface is considered to have timed out Field values (Others are reserved): 3'b000 - 1024 clock cycles 3'b001 - 4096 clock cycles 3'b010 - 16,384 clock cycles 3'b011 - 65,536 clock cycles 3'b100 - 262,144 clock cycles 3'b101 - 1,048,576 clock cycles 3'b110 - 2,097,152 clock cycles 3'b111 - 4,194,303 clock cycles
0x6694 CFG0_MAIN_MTOG37_CTRL_PROXY access per field — Controls timeout operation of Accelerator Cluster QueueManager master accesses to DDR for OrderIDs 5-9
  [31] MAIN_MTOG37_CTRL_IDLE_STAT_PROXY ro — Idle statusWhen high, indicates MTOG37 is idle.
  [23:16] MAIN_MTOG37_CTRL_FORCE_TIMEOUT_PROXY rw — Force TimeoutForces a flush of the interface transactions. This bitfield is only relevant if timeout_en=1. After forcing a timeout by writing the encoded value, the force_timeout and timeout_en bitfields must be cleared to clear the timeout before re-enabling the gasket. 8'h95 - Force a gasket timeoutAll others - Normal operation
  [15] MAIN_MTOG37_CTRL_TIMEOUT_EN_PROXY rw — Timeout Enable 1'b0 - Disable the gasket. Clear the interrupt and reset the counter 1'b1 - Enable the timeout gasket functions
  [2:0] MAIN_MTOG37_CTRL_TIMEOUT_VAL_PROXY rw — Gasket Timeout ValueSelects the number of clock cycles before the interface is considered to have timed out Field values (Others are reserved): 3'b000 - 1024 clock cycles 3'b001 - 4096 clock cycles 3'b010 - 16,384 clock cycles 3'b011 - 65,536 clock cycles 3'b100 - 262,144 clock cycles 3'b101 - 1,048,576 clock cycles 3'b110 - 2,097,152 clock cycles 3'b111 - 4,194,303 clock cycles
0x6698 CFG0_MAIN_MTOG38_CTRL_PROXY access per field — Controls timeout operation of Accelerator Cluster ASIL-B master accesses to DDR for OrderIDs 10-15
  [31] MAIN_MTOG38_CTRL_IDLE_STAT_PROXY ro — Idle statusWhen high, indicates MTOG38 is idle.
  [23:16] MAIN_MTOG38_CTRL_FORCE_TIMEOUT_PROXY rw — Force TimeoutForces a flush of the interface transactions. This bitfield is only relevant if timeout_en=1. After forcing a timeout by writing the encoded value, the force_timeout and timeout_en bitfields must be cleared to clear the timeout before re-enabling the gasket. 8'h95 - Force a gasket timeoutAll others - Normal operation
  [15] MAIN_MTOG38_CTRL_TIMEOUT_EN_PROXY rw — Timeout Enable 1'b0 - Disable the gasket. Clear the interrupt and reset the counter 1'b1 - Enable the timeout gasket functions
  [2:0] MAIN_MTOG38_CTRL_TIMEOUT_VAL_PROXY rw — Gasket Timeout ValueSelects the number of clock cycles before the interface is considered to have timed out Field values (Others are reserved): 3'b000 - 1024 clock cycles 3'b001 - 4096 clock cycles 3'b010 - 16,384 clock cycles 3'b011 - 65,536 clock cycles 3'b100 - 262,144 clock cycles 3'b101 - 1,048,576 clock cycles 3'b110 - 2,097,152 clock cycles 3'b111 - 4,194,303 clock cycles
0x669C CFG0_MAIN_MTOG39_CTRL_PROXY access per field — Controls timeout operation of Accelerator Cluster QueueManager master accesses to DDR for OrderIDs 10-15
  [31] MAIN_MTOG39_CTRL_IDLE_STAT_PROXY ro — Idle statusWhen high, indicates MTOG39 is idle.
  [23:16] MAIN_MTOG39_CTRL_FORCE_TIMEOUT_PROXY rw — Force TimeoutForces a flush of the interface transactions. This bitfield is only relevant if timeout_en=1. After forcing a timeout by writing the encoded value, the force_timeout and timeout_en bitfields must be cleared to clear the timeout before re-enabling the gasket. 8'h95 - Force a gasket timeoutAll others - Normal operation
  [15] MAIN_MTOG39_CTRL_TIMEOUT_EN_PROXY rw — Timeout Enable 1'b0 - Disable the gasket. Clear the interrupt and reset the counter 1'b1 - Enable the timeout gasket functions
  [2:0] MAIN_MTOG39_CTRL_TIMEOUT_VAL_PROXY rw — Gasket Timeout ValueSelects the number of clock cycles before the interface is considered to have timed out Field values (Others are reserved): 3'b000 - 1024 clock cycles 3'b001 - 4096 clock cycles 3'b010 - 16,384 clock cycles 3'b011 - 65,536 clock cycles 3'b100 - 262,144 clock cycles 3'b101 - 1,048,576 clock cycles 3'b110 - 2,097,152 clock cycles 3'b111 - 4,194,303 clock cycles
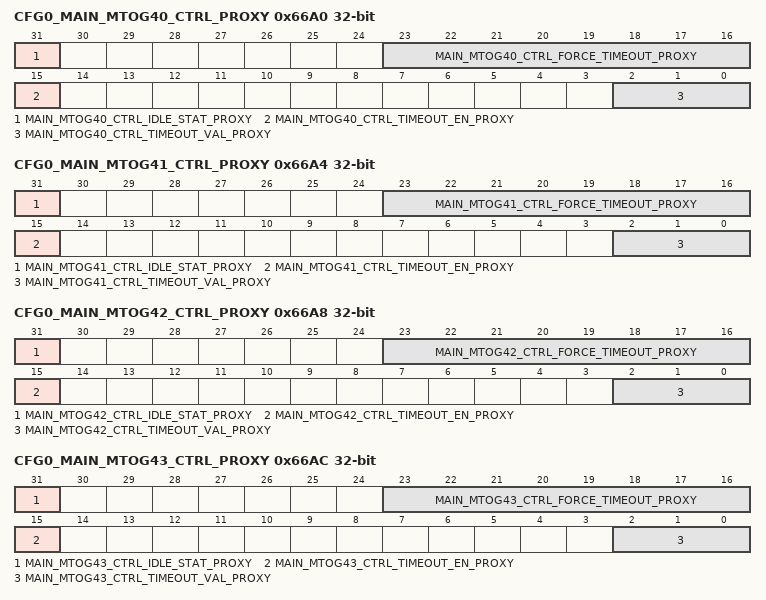
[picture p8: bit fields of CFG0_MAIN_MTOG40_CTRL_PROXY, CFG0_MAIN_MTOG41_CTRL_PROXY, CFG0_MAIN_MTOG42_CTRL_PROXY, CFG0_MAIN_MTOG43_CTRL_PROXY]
0x66A0 CFG0_MAIN_MTOG40_CTRL_PROXY access per field — Controls timeout operation of read transactions from the MAIN R5 Clstr2 Core0 VBUSM Memory master port
  [31] MAIN_MTOG40_CTRL_IDLE_STAT_PROXY ro — Idle statusWhen high, indicates MTOG40 is idle.
  [23:16] MAIN_MTOG40_CTRL_FORCE_TIMEOUT_PROXY rw — Force TimeoutForces a flush of the interface transactions. This bitfield is only relevant if timeout_en=1. After forcing a timeout by writing the encoded value, the force_timeout and timeout_en bitfields must be cleared to clear the timeout before re-enabling the gasket. 8'h95 - Force a gasket timeoutAll others - Normal operation
  [15] MAIN_MTOG40_CTRL_TIMEOUT_EN_PROXY rw — Timeout Enable 1'b0 - Disable the gasket. Clear the interrupt and reset the counter 1'b1 - Enable the timeout gasket functions
  [2:0] MAIN_MTOG40_CTRL_TIMEOUT_VAL_PROXY rw — Gasket Timeout ValueSelects the number of clock cycles before the interface is considered to have timed out Field values (Others are reserved): 3'b000 - 1024 clock cycles 3'b001 - 4096 clock cycles 3'b010 - 16,384 clock cycles 3'b011 - 65,536 clock cycles 3'b100 - 262,144 clock cycles 3'b101 - 1,048,576 clock cycles 3'b110 - 2,097,152 clock cycles 3'b111 - 4,194,303 clock cycles
0x66A4 CFG0_MAIN_MTOG41_CTRL_PROXY access per field — Controls timeout operation of write transactions from the MAIN R5 Clstr2 Core0 VBUSM Memory master port
  [31] MAIN_MTOG41_CTRL_IDLE_STAT_PROXY ro — Idle statusWhen high, indicates MTOG41 is idle.
  [23:16] MAIN_MTOG41_CTRL_FORCE_TIMEOUT_PROXY rw — Force TimeoutForces a flush of the interface transactions. This bitfield is only relevant if timeout_en=1. After forcing a timeout by writing the encoded value, the force_timeout and timeout_en bitfields must be cleared to clear the timeout before re-enabling the gasket. 8'h95 - Force a gasket timeoutAll others - Normal operation
  [15] MAIN_MTOG41_CTRL_TIMEOUT_EN_PROXY rw — Timeout Enable 1'b0 - Disable the gasket. Clear the interrupt and reset the counter 1'b1 - Enable the timeout gasket functions
  [2:0] MAIN_MTOG41_CTRL_TIMEOUT_VAL_PROXY rw — Gasket Timeout ValueSelects the number of clock cycles before the interface is considered to have timed out Field values (Others are reserved): 3'b000 - 1024 clock cycles 3'b001 - 4096 clock cycles 3'b010 - 16,384 clock cycles 3'b011 - 65,536 clock cycles 3'b100 - 262,144 clock cycles 3'b101 - 1,048,576 clock cycles 3'b110 - 2,097,152 clock cycles 3'b111 - 4,194,303 clock cycles
0x66A8 CFG0_MAIN_MTOG42_CTRL_PROXY access per field — Controls timeout operation of read transactions from the MAIN R5 Clstr2 Core1 VBUSM Memory master port
  [31] MAIN_MTOG42_CTRL_IDLE_STAT_PROXY ro — Idle statusWhen high, indicates MTOG42 is idle.
  [23:16] MAIN_MTOG42_CTRL_FORCE_TIMEOUT_PROXY rw — Force TimeoutForces a flush of the interface transactions. This bitfield is only relevant if timeout_en=1. After forcing a timeout by writing the encoded value, the force_timeout and timeout_en bitfields must be cleared to clear the timeout before re-enabling the gasket. 8'h95 - Force a gasket timeoutAll others - Normal operation
  [15] MAIN_MTOG42_CTRL_TIMEOUT_EN_PROXY rw — Timeout Enable 1'b0 - Disable the gasket. Clear the interrupt and reset the counter 1'b1 - Enable the timeout gasket functions
  [2:0] MAIN_MTOG42_CTRL_TIMEOUT_VAL_PROXY rw — Gasket Timeout ValueSelects the number of clock cycles before the interface is considered to have timed out Field values (Others are reserved): 3'b000 - 1024 clock cycles 3'b001 - 4096 clock cycles 3'b010 - 16,384 clock cycles 3'b011 - 65,536 clock cycles 3'b100 - 262,144 clock cycles 3'b101 - 1,048,576 clock cycles 3'b110 - 2,097,152 clock cycles 3'b111 - 4,194,303 clock cycles
0x66AC CFG0_MAIN_MTOG43_CTRL_PROXY access per field — Controls timeout operation of write transactions from the MAIN R5 Clstr2 Core1 VBUSM Memory master port
  [31] MAIN_MTOG43_CTRL_IDLE_STAT_PROXY ro — Idle statusWhen high, indicates MTOG43 is idle.
  [23:16] MAIN_MTOG43_CTRL_FORCE_TIMEOUT_PROXY rw — Force TimeoutForces a flush of the interface transactions. This bitfield is only relevant if timeout_en=1. After forcing a timeout by writing the encoded value, the force_timeout and timeout_en bitfields must be cleared to clear the timeout before re-enabling the gasket. 8'h95 - Force a gasket timeoutAll others - Normal operation
  [15] MAIN_MTOG43_CTRL_TIMEOUT_EN_PROXY rw — Timeout Enable 1'b0 - Disable the gasket. Clear the interrupt and reset the counter 1'b1 - Enable the timeout gasket functions
  [2:0] MAIN_MTOG43_CTRL_TIMEOUT_VAL_PROXY rw — Gasket Timeout ValueSelects the number of clock cycles before the interface is considered to have timed out Field values (Others are reserved): 3'b000 - 1024 clock cycles 3'b001 - 4096 clock cycles 3'b010 - 16,384 clock cycles 3'b011 - 65,536 clock cycles 3'b100 - 262,144 clock cycles 3'b101 - 1,048,576 clock cycles 3'b110 - 2,097,152 clock cycles 3'b111 - 4,194,303 clock cycles
0x66C0 CFG0_CC_FLUSH_CTRL0_PROXY — This register is used isolate the MSMC ARM Corepac 0 interface from other MSMC transactions in case of an ARM Corepac access hang. This allows continuation of other MSMC traffic (e.g. R5 processors) without interference. After asserting this flush, the ARM Corepac can be forced through a power cycle sequence to clear the hang condition. (See Compute Cluster Spec for sequence details.)
  [7:0] CC_FLUSH_CTRL0_FLUSH_PROXY — Flush ARM / MSMC Interface TransactionsForces a flush of the A72 MSMC interface. This bit field can be used to force a flush of A72 transactions to the MSMC and force an auto response of any MSMC snoop requests to the A72. An encoded bit value is used to prevent accidental activation of the flush signal. 8'h95 - Force a flush (FFI Mode) condition (flush signal driven high)All others - Normal operation (flush signal driven low)
0x66C4 CFG0_CC_FLUSH_CTRL1_PROXY — This register is used isolate the MSMC ARM Corepac 1 interface from other MSMC transactions in case of an ARM Corepac access hang. This allows continuation of other MSMC traffic (e.g. R5 processors) without interference. After asserting this flush, the ARM Corepac can be forced through a power cycle sequence to clear the hang condition. (See Compute Cluster Spec for sequence details.)
  [7:0] CC_FLUSH_CTRL1_FLUSH_PROXY — Flush ARM / MSMC Interface TransactionsForces a flush of the A72 MSMC interface. This bit field can be used to force a flush of A72 transactions to the MSMC and force an auto response of any MSMC snoop requests to the A72. An encoded bit value is used to prevent accidental activation of the flush signal. 8'h95 - Force a flush (FFI Mode) condition (flush signal driven high)All others - Normal operation (flush signal driven low)
